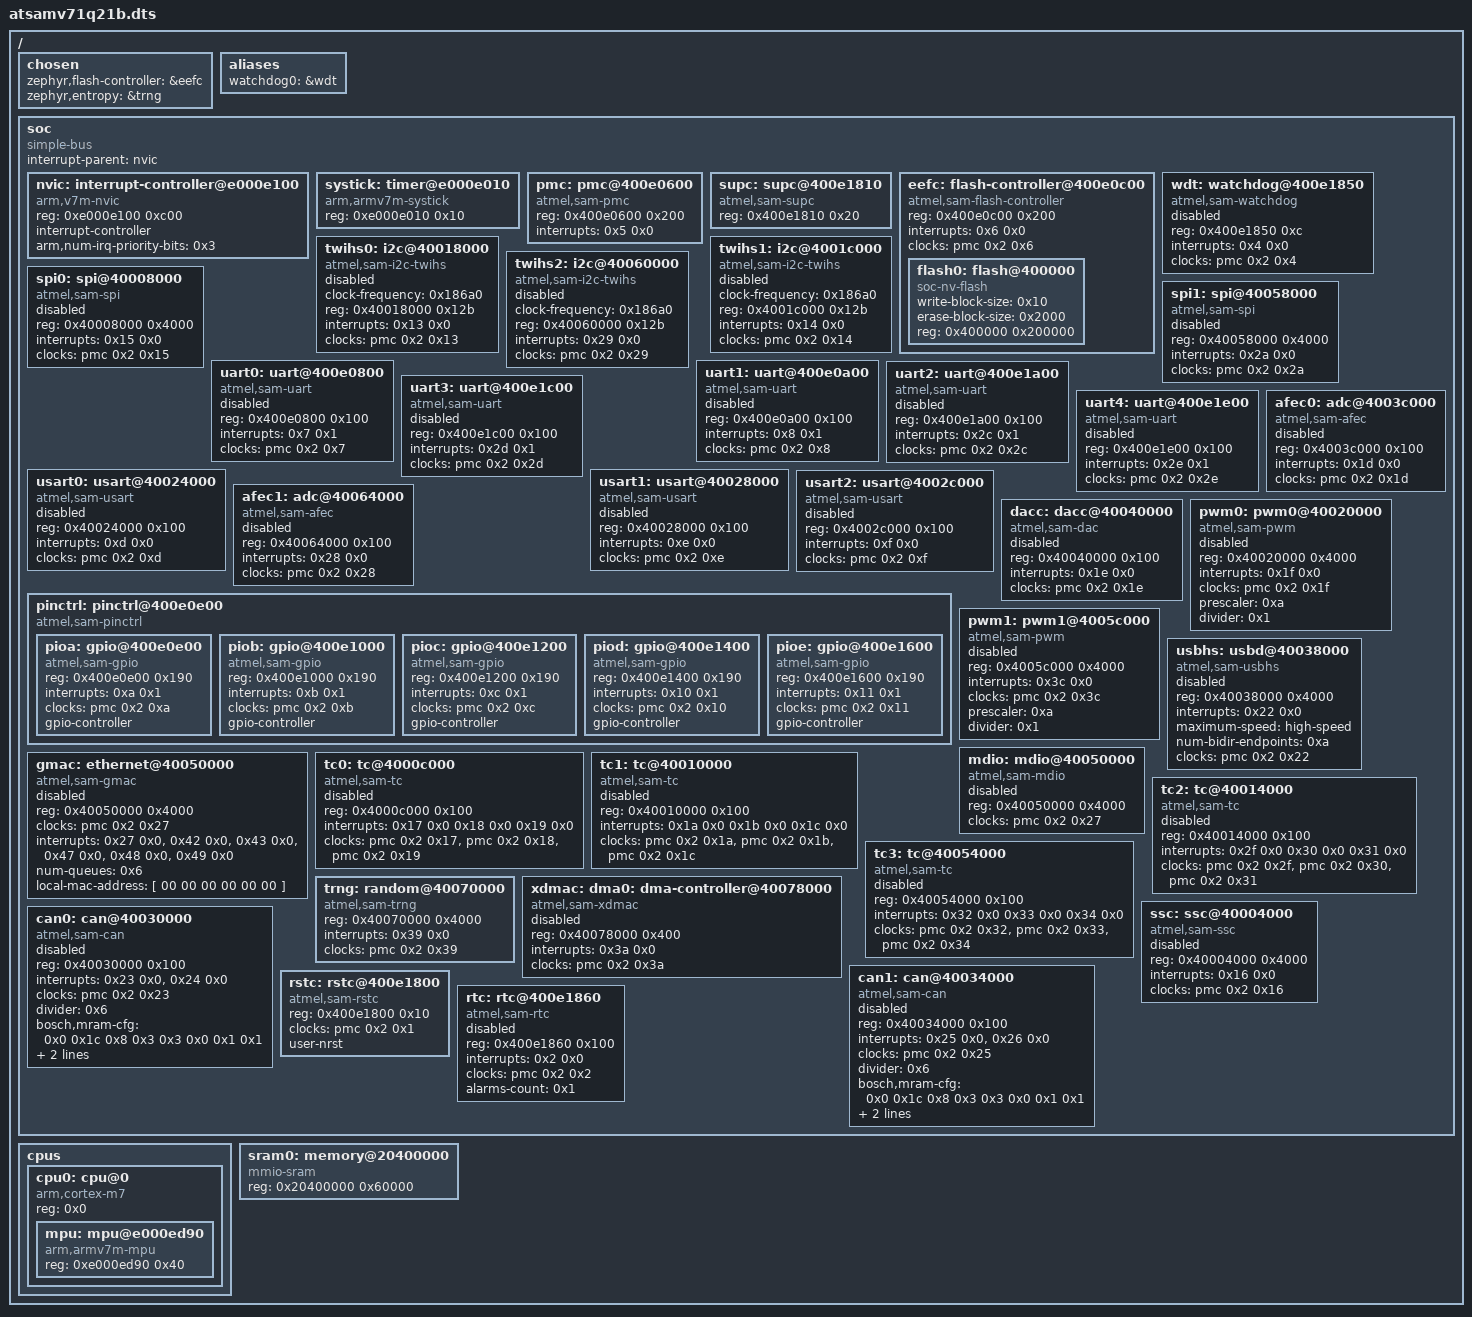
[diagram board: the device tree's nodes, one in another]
/dts-v1/;

/ {
	#address-cells = < 0x1 >;
	#size-cells = < 0x1 >;
	chosen {
		zephyr,flash-controller = &eefc;
		zephyr,entropy = &trng;
	};
	aliases {
		watchdog0 = &wdt;
	};
	soc {
		#address-cells = < 0x1 >;
		#size-cells = < 0x1 >;
		compatible = "simple-bus";
		interrupt-parent = < &nvic >;
		ranges;
		nvic: interrupt-controller@e000e100 {
			#address-cells = < 0x1 >;
			compatible = "arm,v7m-nvic";
			reg = < 0xe000e100 0xc00 >;
			interrupt-controller;
			#interrupt-cells = < 0x2 >;
			arm,num-irq-priority-bits = < 0x3 >;
			phandle = < 0x1 >;
		};
		systick: timer@e000e010 {
			compatible = "arm,armv7m-systick";
			reg = < 0xe000e010 0x10 >;
		};
		pmc: pmc@400e0600 {
			compatible = "atmel,sam-pmc";
			reg = < 0x400e0600 0x200 >;
			interrupts = < 0x5 0x0 >;
			#clock-cells = < 0x2 >;
			status = "okay";
			phandle = < 0x2 >;
		};
		supc: supc@400e1810 {
			compatible = "atmel,sam-supc";
			reg = < 0x400e1810 0x20 >;
			#wakeup-source-id-cells = < 0x1 >;
			status = "okay";
		};
		eefc: flash-controller@400e0c00 {
			compatible = "atmel,sam-flash-controller";
			reg = < 0x400e0c00 0x200 >;
			interrupts = < 0x6 0x0 >;
			clocks = < &pmc 0x2 0x6 >;
			#address-cells = < 0x1 >;
			#size-cells = < 0x1 >;
			flash0: flash@400000 {
				compatible = "soc-nv-flash";
				write-block-size = < 0x10 >;
				erase-block-size = < 0x2000 >;
				reg = < 0x400000 0x200000 >;
			};
		};
		wdt: watchdog@400e1850 {
			compatible = "atmel,sam-watchdog";
			reg = < 0x400e1850 0xc >;
			interrupts = < 0x4 0x0 >;
			clocks = < &pmc 0x2 0x4 >;
			status = "disabled";
		};
		twihs0: i2c@40018000 {
			compatible = "atmel,sam-i2c-twihs";
			clock-frequency = < 0x186a0 >;
			#address-cells = < 0x1 >;
			#size-cells = < 0x0 >;
			reg = < 0x40018000 0x12b >;
			interrupts = < 0x13 0x0 >;
			clocks = < &pmc 0x2 0x13 >;
			status = "disabled";
		};
		twihs1: i2c@4001c000 {
			compatible = "atmel,sam-i2c-twihs";
			clock-frequency = < 0x186a0 >;
			#address-cells = < 0x1 >;
			#size-cells = < 0x0 >;
			reg = < 0x4001c000 0x12b >;
			interrupts = < 0x14 0x0 >;
			clocks = < &pmc 0x2 0x14 >;
			status = "disabled";
		};
		twihs2: i2c@40060000 {
			compatible = "atmel,sam-i2c-twihs";
			clock-frequency = < 0x186a0 >;
			#address-cells = < 0x1 >;
			#size-cells = < 0x0 >;
			reg = < 0x40060000 0x12b >;
			interrupts = < 0x29 0x0 >;
			clocks = < &pmc 0x2 0x29 >;
			status = "disabled";
		};
		spi0: spi@40008000 {
			compatible = "atmel,sam-spi";
			#address-cells = < 0x1 >;
			#size-cells = < 0x0 >;
			reg = < 0x40008000 0x4000 >;
			interrupts = < 0x15 0x0 >;
			clocks = < &pmc 0x2 0x15 >;
			status = "disabled";
		};
		spi1: spi@40058000 {
			compatible = "atmel,sam-spi";
			#address-cells = < 0x1 >;
			#size-cells = < 0x0 >;
			reg = < 0x40058000 0x4000 >;
			interrupts = < 0x2a 0x0 >;
			clocks = < &pmc 0x2 0x2a >;
			status = "disabled";
		};
		uart0: uart@400e0800 {
			compatible = "atmel,sam-uart";
			reg = < 0x400e0800 0x100 >;
			interrupts = < 0x7 0x1 >;
			clocks = < &pmc 0x2 0x7 >;
			status = "disabled";
		};
		uart1: uart@400e0a00 {
			compatible = "atmel,sam-uart";
			reg = < 0x400e0a00 0x100 >;
			interrupts = < 0x8 0x1 >;
			clocks = < &pmc 0x2 0x8 >;
			status = "disabled";
		};
		uart2: uart@400e1a00 {
			compatible = "atmel,sam-uart";
			reg = < 0x400e1a00 0x100 >;
			interrupts = < 0x2c 0x1 >;
			clocks = < &pmc 0x2 0x2c >;
			status = "disabled";
		};
		uart3: uart@400e1c00 {
			compatible = "atmel,sam-uart";
			reg = < 0x400e1c00 0x100 >;
			interrupts = < 0x2d 0x1 >;
			clocks = < &pmc 0x2 0x2d >;
			status = "disabled";
		};
		uart4: uart@400e1e00 {
			compatible = "atmel,sam-uart";
			reg = < 0x400e1e00 0x100 >;
			interrupts = < 0x2e 0x1 >;
			clocks = < &pmc 0x2 0x2e >;
			status = "disabled";
		};
		usart0: usart@40024000 {
			compatible = "atmel,sam-usart";
			reg = < 0x40024000 0x100 >;
			interrupts = < 0xd 0x0 >;
			clocks = < &pmc 0x2 0xd >;
			status = "disabled";
		};
		usart1: usart@40028000 {
			compatible = "atmel,sam-usart";
			reg = < 0x40028000 0x100 >;
			interrupts = < 0xe 0x0 >;
			clocks = < &pmc 0x2 0xe >;
			status = "disabled";
		};
		usart2: usart@4002c000 {
			compatible = "atmel,sam-usart";
			reg = < 0x4002c000 0x100 >;
			interrupts = < 0xf 0x0 >;
			clocks = < &pmc 0x2 0xf >;
			status = "disabled";
		};
		afec0: adc@4003c000 {
			compatible = "atmel,sam-afec";
			reg = < 0x4003c000 0x100 >;
			interrupts = < 0x1d 0x0 >;
			clocks = < &pmc 0x2 0x1d >;
			status = "disabled";
			#io-channel-cells = < 0x1 >;
		};
		afec1: adc@40064000 {
			compatible = "atmel,sam-afec";
			reg = < 0x40064000 0x100 >;
			interrupts = < 0x28 0x0 >;
			clocks = < &pmc 0x2 0x28 >;
			status = "disabled";
			#io-channel-cells = < 0x1 >;
		};
		dacc: dacc@40040000 {
			compatible = "atmel,sam-dac";
			reg = < 0x40040000 0x100 >;
			interrupts = < 0x1e 0x0 >;
			clocks = < &pmc 0x2 0x1e >;
			status = "disabled";
			#io-channel-cells = < 0x1 >;
		};
		pinctrl: pinctrl@400e0e00 {
			compatible = "atmel,sam-pinctrl";
			#address-cells = < 0x1 >;
			#size-cells = < 0x1 >;
			ranges = < 0x400e0e00 0x400e0e00 0xa00 >;
			pioa: gpio@400e0e00 {
				compatible = "atmel,sam-gpio";
				reg = < 0x400e0e00 0x190 >;
				interrupts = < 0xa 0x1 >;
				clocks = < &pmc 0x2 0xa >;
				gpio-controller;
				#gpio-cells = < 0x2 >;
				#atmel,pin-cells = < 0x2 >;
			};
			piob: gpio@400e1000 {
				compatible = "atmel,sam-gpio";
				reg = < 0x400e1000 0x190 >;
				interrupts = < 0xb 0x1 >;
				clocks = < &pmc 0x2 0xb >;
				gpio-controller;
				#gpio-cells = < 0x2 >;
				#atmel,pin-cells = < 0x2 >;
			};
			pioc: gpio@400e1200 {
				compatible = "atmel,sam-gpio";
				reg = < 0x400e1200 0x190 >;
				interrupts = < 0xc 0x1 >;
				clocks = < &pmc 0x2 0xc >;
				gpio-controller;
				#gpio-cells = < 0x2 >;
				#atmel,pin-cells = < 0x2 >;
			};
			piod: gpio@400e1400 {
				compatible = "atmel,sam-gpio";
				reg = < 0x400e1400 0x190 >;
				interrupts = < 0x10 0x1 >;
				clocks = < &pmc 0x2 0x10 >;
				gpio-controller;
				#gpio-cells = < 0x2 >;
				#atmel,pin-cells = < 0x2 >;
			};
			pioe: gpio@400e1600 {
				compatible = "atmel,sam-gpio";
				reg = < 0x400e1600 0x190 >;
				interrupts = < 0x11 0x1 >;
				clocks = < &pmc 0x2 0x11 >;
				gpio-controller;
				#gpio-cells = < 0x2 >;
				#atmel,pin-cells = < 0x2 >;
			};
		};
		pwm0: pwm0@40020000 {
			compatible = "atmel,sam-pwm";
			reg = < 0x40020000 0x4000 >;
			interrupts = < 0x1f 0x0 >;
			clocks = < &pmc 0x2 0x1f >;
			status = "disabled";
			prescaler = < 0xa >;
			divider = < 0x1 >;
			#pwm-cells = < 0x3 >;
		};
		pwm1: pwm1@4005c000 {
			compatible = "atmel,sam-pwm";
			reg = < 0x4005c000 0x4000 >;
			interrupts = < 0x3c 0x0 >;
			clocks = < &pmc 0x2 0x3c >;
			status = "disabled";
			prescaler = < 0xa >;
			divider = < 0x1 >;
			#pwm-cells = < 0x3 >;
		};
		usbhs: usbd@40038000 {
			compatible = "atmel,sam-usbhs";
			#address-cells = < 0x1 >;
			#size-cells = < 0x0 >;
			reg = < 0x40038000 0x4000 >;
			interrupts = < 0x22 0x0 >;
			interrupt-names = "usbhs";
			maximum-speed = "high-speed";
			num-bidir-endpoints = < 0xa >;
			clocks = < &pmc 0x2 0x22 >;
			status = "disabled";
		};
		gmac: ethernet@40050000 {
			compatible = "atmel,sam-gmac";
			reg = < 0x40050000 0x4000 >;
			clocks = < &pmc 0x2 0x27 >;
			interrupts = < 0x27 0x0 >, < 0x42 0x0 >, < 0x43 0x0 >, < 0x47 0x0 >, < 0x48 0x0 >, < 0x49 0x0 >;
			interrupt-names = "gmac", "q1", "q2", "q3", "q4", "q5";
			num-queues = < 0x6 >;
			local-mac-address = [ 00 00 00 00 00 00 ];
			status = "disabled";
		};
		mdio: mdio@40050000 {
			compatible = "atmel,sam-mdio";
			reg = < 0x40050000 0x4000 >;
			clocks = < &pmc 0x2 0x27 >;
			status = "disabled";
			#address-cells = < 0x1 >;
			#size-cells = < 0x0 >;
		};
		tc0: tc@4000c000 {
			compatible = "atmel,sam-tc";
			reg = < 0x4000c000 0x100 >;
			interrupts = < 0x17 0x0 0x18 0x0 0x19 0x0 >;
			clocks = < &pmc 0x2 0x17 >, < &pmc 0x2 0x18 >, < &pmc 0x2 0x19 >;
			status = "disabled";
		};
		tc1: tc@40010000 {
			compatible = "atmel,sam-tc";
			reg = < 0x40010000 0x100 >;
			interrupts = < 0x1a 0x0 0x1b 0x0 0x1c 0x0 >;
			clocks = < &pmc 0x2 0x1a >, < &pmc 0x2 0x1b >, < &pmc 0x2 0x1c >;
			status = "disabled";
		};
		tc2: tc@40014000 {
			compatible = "atmel,sam-tc";
			reg = < 0x40014000 0x100 >;
			interrupts = < 0x2f 0x0 0x30 0x0 0x31 0x0 >;
			clocks = < &pmc 0x2 0x2f >, < &pmc 0x2 0x30 >, < &pmc 0x2 0x31 >;
			status = "disabled";
		};
		tc3: tc@40054000 {
			compatible = "atmel,sam-tc";
			reg = < 0x40054000 0x100 >;
			interrupts = < 0x32 0x0 0x33 0x0 0x34 0x0 >;
			clocks = < &pmc 0x2 0x32 >, < &pmc 0x2 0x33 >, < &pmc 0x2 0x34 >;
			status = "disabled";
		};
		trng: random@40070000 {
			compatible = "atmel,sam-trng";
			reg = < 0x40070000 0x4000 >;
			interrupts = < 0x39 0x0 >;
			clocks = < &pmc 0x2 0x39 >;
			status = "okay";
		};
		xdmac: dma0: dma-controller@40078000 {
			compatible = "atmel,sam-xdmac";
			reg = < 0x40078000 0x400 >;
			interrupts = < 0x3a 0x0 >;
			clocks = < &pmc 0x2 0x3a >;
			#dma-cells = < 0x2 >;
			status = "disabled";
		};
		ssc: ssc@40004000 {
			compatible = "atmel,sam-ssc";
			reg = < 0x40004000 0x4000 >;
			interrupts = < 0x16 0x0 >;
			clocks = < &pmc 0x2 0x16 >;
			status = "disabled";
		};
		can0: can@40030000 {
			compatible = "atmel,sam-can";
			reg = < 0x40030000 0x100 >;
			interrupts = < 0x23 0x0 >, < 0x24 0x0 >;
			interrupt-names = "int0", "int1";
			clocks = < &pmc 0x2 0x23 >;
			divider = < 0x6 >;
			bosch,mram-cfg = < 0x0 0x1c 0x8 0x3 0x3 0x0 0x1 0x1 >;
			sample-point = < 0x36b >;
			sample-point-data = < 0x36b >;
			status = "disabled";
		};
		can1: can@40034000 {
			compatible = "atmel,sam-can";
			reg = < 0x40034000 0x100 >;
			interrupts = < 0x25 0x0 >, < 0x26 0x0 >;
			interrupt-names = "int0", "int1";
			clocks = < &pmc 0x2 0x25 >;
			divider = < 0x6 >;
			bosch,mram-cfg = < 0x0 0x1c 0x8 0x3 0x3 0x0 0x1 0x1 >;
			sample-point = < 0x36b >;
			sample-point-data = < 0x36b >;
			status = "disabled";
		};
		rstc: rstc@400e1800 {
			compatible = "atmel,sam-rstc";
			reg = < 0x400e1800 0x10 >;
			clocks = < &pmc 0x2 0x1 >;
			user-nrst;
		};
		rtc: rtc@400e1860 {
			compatible = "atmel,sam-rtc";
			reg = < 0x400e1860 0x100 >;
			interrupts = < 0x2 0x0 >;
			clocks = < &pmc 0x2 0x2 >;
			alarms-count = < 0x1 >;
			status = "disabled";
		};
	};
	cpus {
		#address-cells = < 0x1 >;
		#size-cells = < 0x0 >;
		cpu0: cpu@0 {
			device_type = "cpu";
			compatible = "arm,cortex-m7";
			reg = < 0x0 >;
			#address-cells = < 0x1 >;
			#size-cells = < 0x1 >;
			mpu: mpu@e000ed90 {
				compatible = "arm,armv7m-mpu";
				reg = < 0xe000ed90 0x40 >;
			};
		};
	};
	sram0: memory@20400000 {
		compatible = "mmio-sram";
		reg = < 0x20400000 0x60000 >;
	};
};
